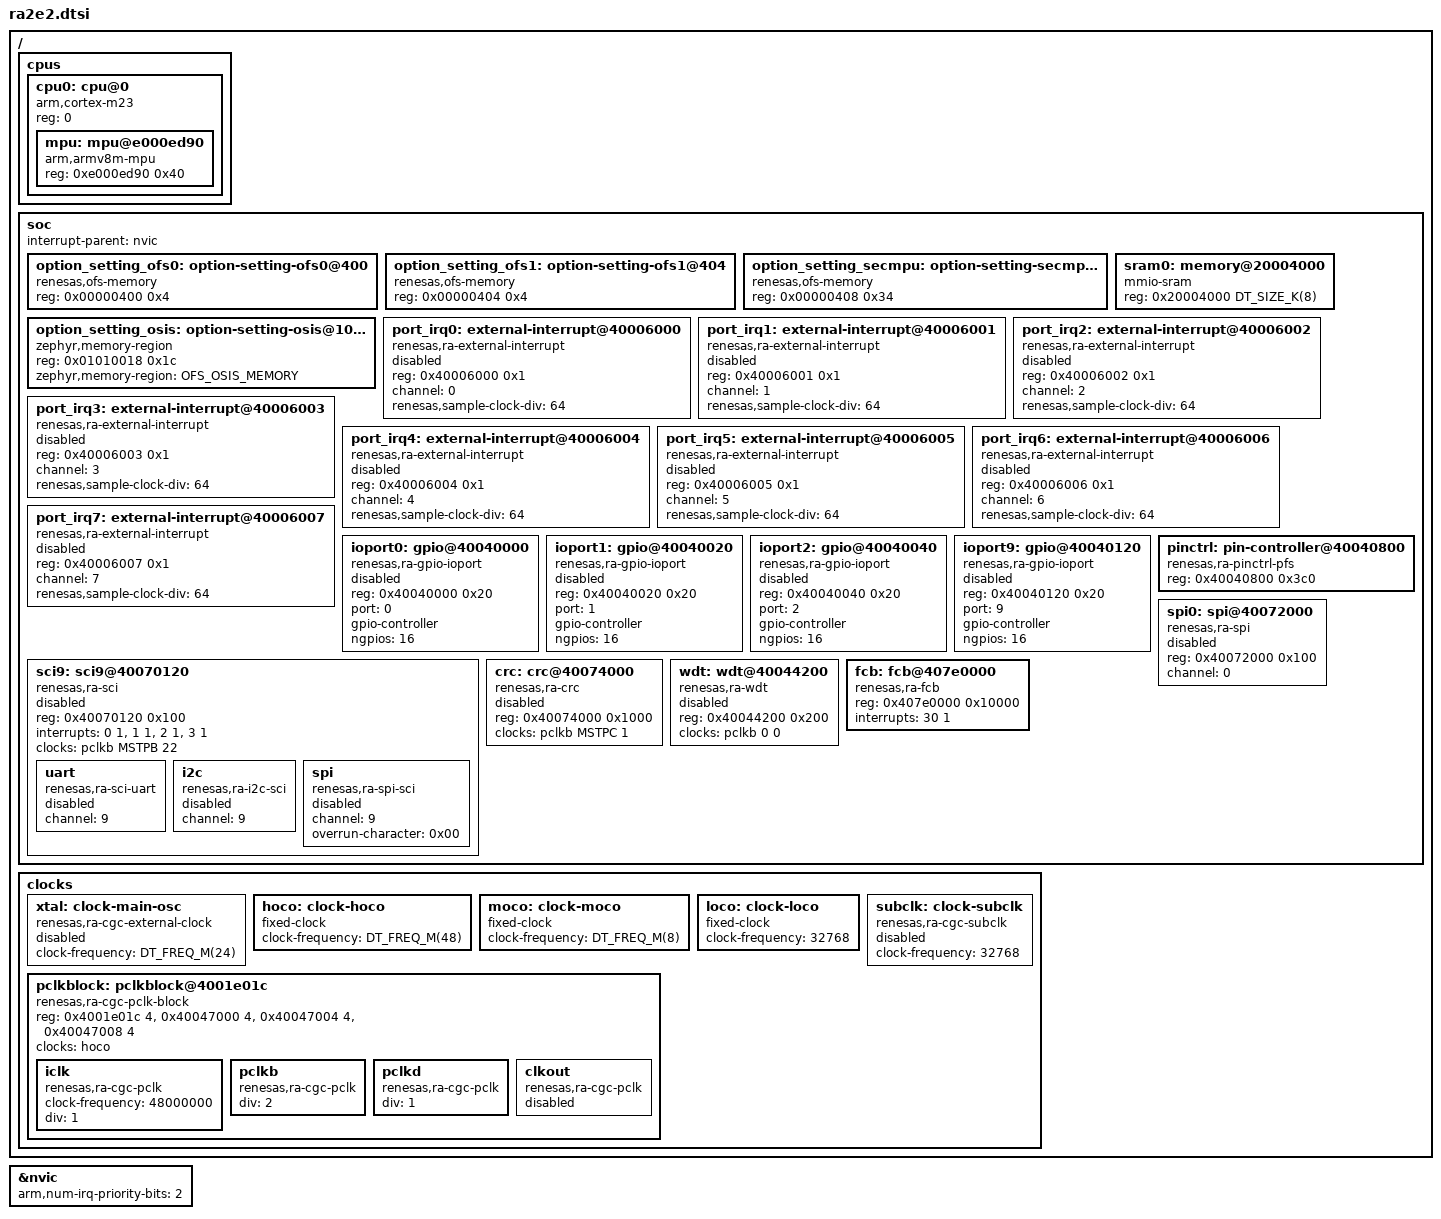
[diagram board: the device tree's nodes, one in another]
/*
 * Copyright (c) 2026 Renesas Electronics Corporation
 *
 * Renesas RA2E2 MCU series device tree
 *
 * SPDX-License-Identifier: Apache-2.0
 */

#include <freq.h>
#include <mem.h>
#include <arm/armv8-m.dtsi>
#include <zephyr/dt-bindings/pinctrl/renesas/pinctrl-ra.h>
#include <zephyr/dt-bindings/clock/ra_clock.h>
#include <zephyr/dt-bindings/pwm/ra_pwm.h>
#include <zephyr/dt-bindings/i2c/i2c.h>

/ {
	cpus {
		#address-cells = <1>;
		#size-cells = <0>;

		cpu0: cpu@0 {
			compatible = "arm,cortex-m23";
			reg = <0>;
			device_type = "cpu";
			#address-cells = <1>;
			#size-cells = <1>;

			mpu: mpu@e000ed90 {
				compatible = "arm,armv8m-mpu";
				reg = <0xe000ed90 0x40>;
			};
		};
	};

	soc {
		interrupt-parent = <&nvic>;

		option_setting_ofs0: option-setting-ofs0@400 {
			compatible = "renesas,ofs-memory";
			reg = <0x00000400 0x4>;
			status = "okay";
		};

		option_setting_ofs1: option-setting-ofs1@404 {
			compatible = "renesas,ofs-memory";
			reg = <0x00000404 0x4>;
			status = "okay";
		};

		option_setting_secmpu: option-setting-secmpu@408 {
			compatible = "renesas,ofs-memory";
			reg = <0x00000408 0x34>;
			status = "okay";
		};

		option_setting_osis: option-setting-osis@1010018 {
			compatible = "zephyr,memory-region";
			reg = <0x01010018 0x1c>;
			zephyr,memory-region = "OFS_OSIS_MEMORY";
			status = "okay";
		};

		/* HW UM Fig 4.1: on-chip SRAM at 0x20004000, 8 KB */
		sram0: memory@20004000 {
			compatible = "mmio-sram";
			reg = <0x20004000 DT_SIZE_K(8)>;
		};

		port_irq0: external-interrupt@40006000 {
			compatible = "renesas,ra-external-interrupt";
			reg = <0x40006000 0x1>;
			channel = <0>;
			#port-irq-cells = <0>;
			renesas,sample-clock-div = <64>;
			status = "disabled";
		};

		port_irq1: external-interrupt@40006001 {
			compatible = "renesas,ra-external-interrupt";
			reg = <0x40006001 0x1>;
			channel = <1>;
			#port-irq-cells = <0>;
			renesas,sample-clock-div = <64>;
			status = "disabled";
		};

		port_irq2: external-interrupt@40006002 {
			compatible = "renesas,ra-external-interrupt";
			reg = <0x40006002 0x1>;
			channel = <2>;
			#port-irq-cells = <0>;
			renesas,sample-clock-div = <64>;
			status = "disabled";
		};

		port_irq3: external-interrupt@40006003 {
			compatible = "renesas,ra-external-interrupt";
			reg = <0x40006003 0x1>;
			channel = <3>;
			#port-irq-cells = <0>;
			renesas,sample-clock-div = <64>;
			status = "disabled";
		};

		port_irq4: external-interrupt@40006004 {
			compatible = "renesas,ra-external-interrupt";
			reg = <0x40006004 0x1>;
			channel = <4>;
			#port-irq-cells = <0>;
			renesas,sample-clock-div = <64>;
			status = "disabled";
		};

		port_irq5: external-interrupt@40006005 {
			compatible = "renesas,ra-external-interrupt";
			reg = <0x40006005 0x1>;
			channel = <5>;
			#port-irq-cells = <0>;
			renesas,sample-clock-div = <64>;
			status = "disabled";
		};

		port_irq6: external-interrupt@40006006 {
			compatible = "renesas,ra-external-interrupt";
			reg = <0x40006006 0x1>;
			channel = <6>;
			#port-irq-cells = <0>;
			renesas,sample-clock-div = <64>;
			status = "disabled";
		};

		port_irq7: external-interrupt@40006007 {
			compatible = "renesas,ra-external-interrupt";
			reg = <0x40006007 0x1>;
			channel = <7>;
			#port-irq-cells = <0>;
			renesas,sample-clock-div = <64>;
			status = "disabled";
		};

		ioport0: gpio@40040000 {
			compatible = "renesas,ra-gpio-ioport";
			reg = <0x40040000 0x20>;
			port = <0>;
			gpio-controller;
			#gpio-cells = <2>;
			ngpios = <16>;
			status = "disabled";
		};

		ioport1: gpio@40040020 {
			compatible = "renesas,ra-gpio-ioport";
			reg = <0x40040020 0x20>;
			port = <1>;
			gpio-controller;
			#gpio-cells = <2>;
			ngpios = <16>;
			status = "disabled";
		};

		ioport2: gpio@40040040 {
			compatible = "renesas,ra-gpio-ioport";
			reg = <0x40040040 0x20>;
			port = <2>;
			gpio-controller;
			#gpio-cells = <2>;
			ngpios = <16>;
			status = "disabled";
		};

		ioport9: gpio@40040120 {
			compatible = "renesas,ra-gpio-ioport";
			reg = <0x40040120 0x20>;
			port = <9>;
			gpio-controller;
			#gpio-cells = <2>;
			ngpios = <16>;
			status = "disabled";
		};

		pinctrl: pin-controller@40040800 {
			compatible = "renesas,ra-pinctrl-pfs";
			reg = <0x40040800 0x3c0>;
			status = "okay";
		};

		/* Only SCI9 present on RA2E2 */
		sci9: sci9@40070120 {
			compatible = "renesas,ra-sci";
			reg = <0x40070120 0x100>;
			interrupts = <0 1>, <1 1>, <2 1>, <3 1>;
			interrupt-names = "rxi", "txi", "tei", "eri";
			clocks = <&pclkb MSTPB 22>;
			status = "disabled";

			uart {
				compatible = "renesas,ra-sci-uart";
				channel = <9>;
				status = "disabled";
			};

			i2c {
				compatible = "renesas,ra-i2c-sci";
				#address-cells = <1>;
				#size-cells = <0>;
				channel = <9>;
				status = "disabled";
			};

			spi {
				compatible = "renesas,ra-spi-sci";
				#address-cells = <1>;
				#size-cells = <0>;
				channel = <9>;
				overrun-character = <0x00>;
				status = "disabled";
			};
		};

		spi0: spi@40072000 {
			compatible = "renesas,ra-spi";
			reg = <0x40072000 0x100>;
			#address-cells = <1>;
			#size-cells = <0>;
			channel = <0>;
			status = "disabled";
		};

		crc: crc@40074000 {
			compatible = "renesas,ra-crc";
			reg = <0x40074000 0x1000>;
			clocks = <&pclkb MSTPC 1>;
			status = "disabled";
		};

		wdt: wdt@40044200 {
			compatible = "renesas,ra-wdt";
			reg = <0x40044200 0x200>;
			clocks = <&pclkb 0 0>;
			status = "disabled";
		};

		fcb: fcb@407e0000 {
			compatible = "renesas,ra-fcb";
			reg = <0x407e0000 0x10000>;
			ranges;
			interrupts = <30 1>;
			interrupt-names = "frdyi";
		};
	};

	clocks: clocks {
		#address-cells = <1>;
		#size-cells = <1>;

		xtal: clock-main-osc {
			compatible = "renesas,ra-cgc-external-clock";
			clock-frequency = <DT_FREQ_M(24)>;
			#clock-cells = <0>;
			status = "disabled";
		};

		hoco: clock-hoco {
			compatible = "fixed-clock";
			clock-frequency = <DT_FREQ_M(48)>;
			#clock-cells = <0>;
		};

		moco: clock-moco {
			compatible = "fixed-clock";
			clock-frequency = <DT_FREQ_M(8)>;
			#clock-cells = <0>;
		};

		loco: clock-loco {
			compatible = "fixed-clock";
			clock-frequency = <32768>;
			#clock-cells = <0>;
		};

		subclk: clock-subclk {
			compatible = "renesas,ra-cgc-subclk";
			clock-frequency = <32768>;
			#clock-cells = <0>;
			status = "disabled";
		};

		pclkblock: pclkblock@4001e01c {
			compatible = "renesas,ra-cgc-pclk-block";
			reg = <0x4001e01c 4>, <0x40047000 4>, <0x40047004 4>,
			      <0x40047008 4>;
			reg-names = "MSTPA", "MSTPB", "MSTPC",
				    "MSTPD";
			#clock-cells = <0>;
			clocks = <&hoco>;
			status = "okay";

			iclk: iclk {
				compatible = "renesas,ra-cgc-pclk";
				clock-frequency = <48000000>;
				div = <1>;
				#clock-cells = <2>;
				status = "okay";
			};

			pclkb: pclkb {
				compatible = "renesas,ra-cgc-pclk";
				div = <2>;
				#clock-cells = <2>;
				status = "okay";
			};

			pclkd: pclkd {
				compatible = "renesas,ra-cgc-pclk";
				div = <1>;
				#clock-cells = <2>;
				status = "okay";
			};

			clkout: clkout {
				compatible = "renesas,ra-cgc-pclk";
				#clock-cells = <2>;
				status = "disabled";
			};
		};
	};
};

&nvic {
	arm,num-irq-priority-bits = <2>;
};
